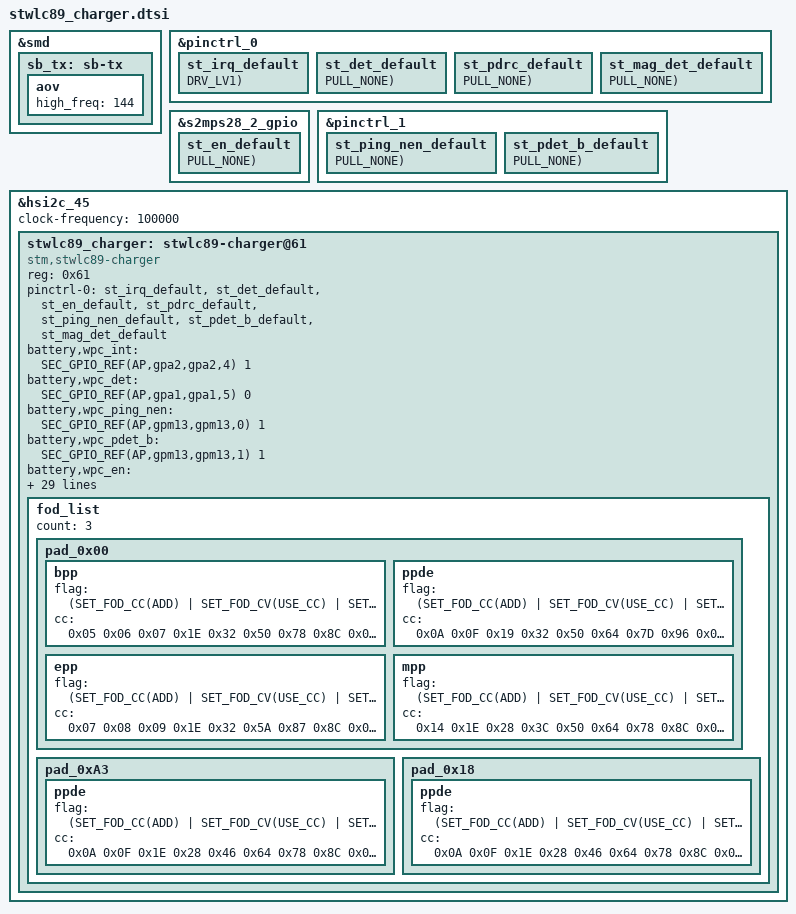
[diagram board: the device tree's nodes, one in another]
#include <dt-bindings/battery/sec-battery.h>

&smd {
	sb_tx: sb-tx {
	       aov {
		       high_freq = <144>;
	       };
       };
};

&pinctrl_0 {
	st_irq_default: st_irq_default {
		GPIO_CONFIG_PUD_DRV(AP,gpa2,gpa2,4, FUNC_INPUT_WAKEUP, PULL_NONE, DRV_LV1);
	};
};

&pinctrl_0 {
	st_det_default: st_det_default {
		GPIO_CONFIG_PUD(AP,gpa1,gpa1,5, FUNC_INPUT_WAKEUP, PULL_NONE);
	};
};

&s2mps28_2_gpio {
	st_en_default: st_en_default {
		GPIO_CONFIG_PUD(PM,s2mps28_2_gpio,gpio_s,5, FUNC_OUTPUT_LOW, PULL_NONE);
	};
};

#if 1
&pinctrl_0 {
	st_pdrc_default: st_pdrc_default {
		GPIO_CONFIG_PUD(AP,gpa3,gpa3,2, FUNC_INPUT_WAKEUP, PULL_NONE);
	};
};
#endif

#if 1
&pinctrl_1 {
	st_ping_nen_default: st_ping_nen_default {
		GPIO_CONFIG_PUD(AP,gpm13,gpm13,0, FUNC_OUTPUT_HIGH, PULL_NONE);
	};
};
#endif

#if 1
&pinctrl_1 {
	st_pdet_b_default: st_pdet_b_default {
		GPIO_CONFIG_PUD(AP,gpm13,gpm13,1, FUNC_INPUT_WAKEUP, PULL_NONE);
	};
};
#endif

#if 1
&pinctrl_0 {
	st_mag_det_default: st_mag_det_default {
		GPIO_CONFIG_PUD(AP,gpa2,gpa2,7, FUNC_OUTPUT_HIGH, PULL_NONE);
	};
};
#endif

#if 0
&${wpc_mode_parent} {
	st_wpc_mode_default: st_wpc_mode_default {
		GPIO_CONFIG_PUD(${st_wpc_mode_gpio}, FUNC_OUTPUT_HIGH, PULL_NONE);
	};
};
#endif

#if 0
&${temp_nen_parent} {
	st_temp_nen_default: st_temp_nen_default {
		GPIO_CONFIG_PUD(${st_temp_nen_gpio}, FUNC_OUTPUT_LOW, PULL_NONE);
	};
};
#endif

&hsi2c_45 {
	#address-cells = <1>;
	#size-cells = <0>;
	status = "okay";
	clock-frequency = <100000>;

	stwlc89_charger: stwlc89-charger@61 {
		compatible = "stm,stwlc89-charger";
		reg = <0x61>;
		status = "okay";

		pinctrl-names = "default";
		pinctrl-0 = <&st_irq_default &st_det_default &st_en_default &st_pdrc_default
#if 1
			&st_ping_nen_default
#endif
#if 1
			&st_pdet_b_default
#endif
#if 1
			&st_mag_det_default
#endif
#if 0
			&st_wpc_mode_default
#endif
#if 0
			&st_temp_nen_default
#endif
			>;

		battery,wpc_int = <SEC_GPIO_REF(AP,gpa2,gpa2,4) 1>; /* MFC_AP_INT */
		battery,wpc_det = <SEC_GPIO_REF(AP,gpa1,gpa1,5) 0>; /* WPC_DET */
#if 0
		battery,mst_pwr_en = <SEC_GPIO_REF(${st_pwr_en_gpio}) 0>; /* MST_PWR_EN */
#endif
#if 1
		battery,wpc_ping_nen = <SEC_GPIO_REF(AP,gpm13,gpm13,0) 1>; /* PING_NEN */
#endif
#if 1
		battery,wpc_pdet_b = <SEC_GPIO_REF(AP,gpm13,gpm13,1) 1>; /* PDET_B */
#endif
		battery,wpc_en = <SEC_GPIO_REF(PM,s2mps28_2_gpio,gpio_s,5) 0>; /* WPC_EN */
#if 1
		battery,wpc_pdrc = <SEC_GPIO_REF(AP,gpa3,gpa3,2) 1>; /* VRECT_INT */
#endif
#if 1
		battery,wpc_mag_det = <SEC_GPIO_REF(AP,gpa2,gpa2,7) 0>; /* MAG_DET */
#endif
#if 0
		battery,wpc_mode = <SEC_GPIO_REF(${st_wpc_mode_gpio}) 0>; /* WPC_MODE */
#endif
#if 0
		battery,temp_nen = <SEC_GPIO_REF(${st_temp_nen_gpio}) 0>; /* TEMP_nEN */
#endif
		battery,charger_name = "max77775-charger";
		battery,fuelgauge_name = "max77775-fuelgauge";
		battery,wireless_charger_name = "stwlc89-charger";
		battery,wc_cover_rpp = <0x44>;
		battery,phone_fod_threshold = <0x3b>;
		battery,wireless20_vout_list = <WIRELESS_VOUT_9V /* 0xA0 */
						WIRELESS_VOUT_12V /* 0xA1 */
						WIRELESS_VOUT_12V /* 0xA2 */
						WIRELESS_VOUT_12V /* 0xA3 */
						WIRELESS_VOUT_12V /* 0xA4 */
						WIRELESS_VOUT_12V>; /* 0xA5 */
		battery,wireless20_vrect_list = <MFC_AFC_CONF_12V_TX
						MFC_AFC_CONF_12_5V_TX
						MFC_AFC_CONF_12_5V_TX
						MFC_AFC_CONF_12_5V_TX
						MFC_AFC_CONF_12_5V_TX
						MFC_AFC_CONF_12_5V_TX>;
		battery,wireless20_max_power_list = <SEC_WIRELESS_RX_POWER_12W
						SEC_WIRELESS_RX_POWER_15W
						SEC_WIRELESS_RX_POWER_15W
						SEC_WIRELESS_RX_POWER_15W
						SEC_WIRELESS_RX_POWER_15W
						SEC_WIRELESS_RX_POWER_15W>;

		battery,buds_fod_ta_thresh = <0x0898>; /* 2200mW */
		battery,wpc_vout_ctrl_full = <WIRELESS_VOUT_5V_STEP>;
		battery,mis_align_guide;
		battery,mis_align_target_vout = <5000>;
		battery,mpp_epp_vout = <WIRELESS_VOUT_12V>;

		fod_list {
			count = <3>;

			pad_0x00 { /* DEFAULT PAD */
				bpp { /* DEFAULT OP MODE */
					flag = <(SET_FOD_CC(ADD) | SET_FOD_CV(USE_CC) | SET_FOD_FULL(USE_CC))>;
					cc = <0x05 0x06 0x07 0x1E 0x32 0x50 0x78 0x8C 0x05 0x0A
						0x0A 0x0A 0x0B 0x0C 0x11 0x11 0x11 0x00 0x64 0x00>;
				};

				ppde {
					flag = <(SET_FOD_CC(ADD) | SET_FOD_CV(USE_CC) | SET_FOD_FULL(USE_CC))>;
					cc = <0x0A 0x0F 0x19 0x32 0x50 0x64 0x7D 0x96 0x08 0x0C
						0x0D 0x10 0x14 0x23 0x28 0x2F 0x37 0x00 0x64 0x00>;
				};

				epp {
					flag = <(SET_FOD_CC(ADD) | SET_FOD_CV(USE_CC) | SET_FOD_FULL(USE_CC))>;
					cc = <0x07 0x08 0x09 0x1E 0x32 0x5A 0x87 0x8C 0x0B 0x17
						0x17 0x20 0x1F 0x23 0x32 0x35 0x35 0x00 0x64 0x00>;
				};

				mpp {
					flag = <(SET_FOD_CC(ADD) | SET_FOD_CV(USE_CC) | SET_FOD_FULL(USE_CC))>;
					cc = <0x14 0x1E 0x28 0x3C 0x50 0x64 0x78 0x8C 0x00 0x05
						0x07 0x0A 0x0C 0x10 0x14 0x19 0x23 0x00 0x32 0x00>;
				};
			};
			pad_0xA3 { /* p2400 */
				ppde {
					flag = <(SET_FOD_CC(ADD) | SET_FOD_CV(USE_CC) | SET_FOD_FULL(USE_CC))>;
					cc = <0x0A 0x0F 0x1E 0x28 0x46 0x64 0x78 0x8C 0x0C 0x0E
						0x10 0x1C 0x3E 0x34 0x32 0x3C 0x4B 0x64 0x00 0x00>;
 				};
 			};
			
			pad_0x18 { /* p2400 */
				ppde {
					flag = <(SET_FOD_CC(ADD) | SET_FOD_CV(USE_CC) | SET_FOD_FULL(USE_CC))>;
					cc = <0x0A 0x0F 0x1E 0x28 0x46 0x64 0x78 0x8C 0x0C 0x0E
						0x10 0x1C 0x3E 0x34 0x32 0x3C 0x4B 0x64 0x00 0x00>;
				};
			};	
		};
	};
};

/* /home/dpi/qb5_8814/workspace/P4_1716/android/kernel/kmodule/battery/suwon/wireless/stwlc89/stwlc89_charger.r12s.dtsi */

&stwlc89_charger {
	battery,unknown_cmb_ctrl;
	battery,default_clamp_volt;
	battery,tx_max_op_freq = <1450>;
	battery,tx_min_op_freq = <1120>;
	battery,wireless20_iec_ploss_fod_enable = <0x1>;
	battery,tx_fod_gain = <0x72>;
	battery,buds_fod_thresh1 = <0x0DAC>;
	battery,buds_fod_ta_thresh = <0x0DAC>;
};

/* /home/dpi/qb5_8814/workspace/P4_1716/android/kernel/kmodule/battery/suwon/wireless/stwlc89/stwlc89_charger.r12s.02.dtsi */
/* From HWID02 refer to stwlc89_charger.r12s.dtsi file */
